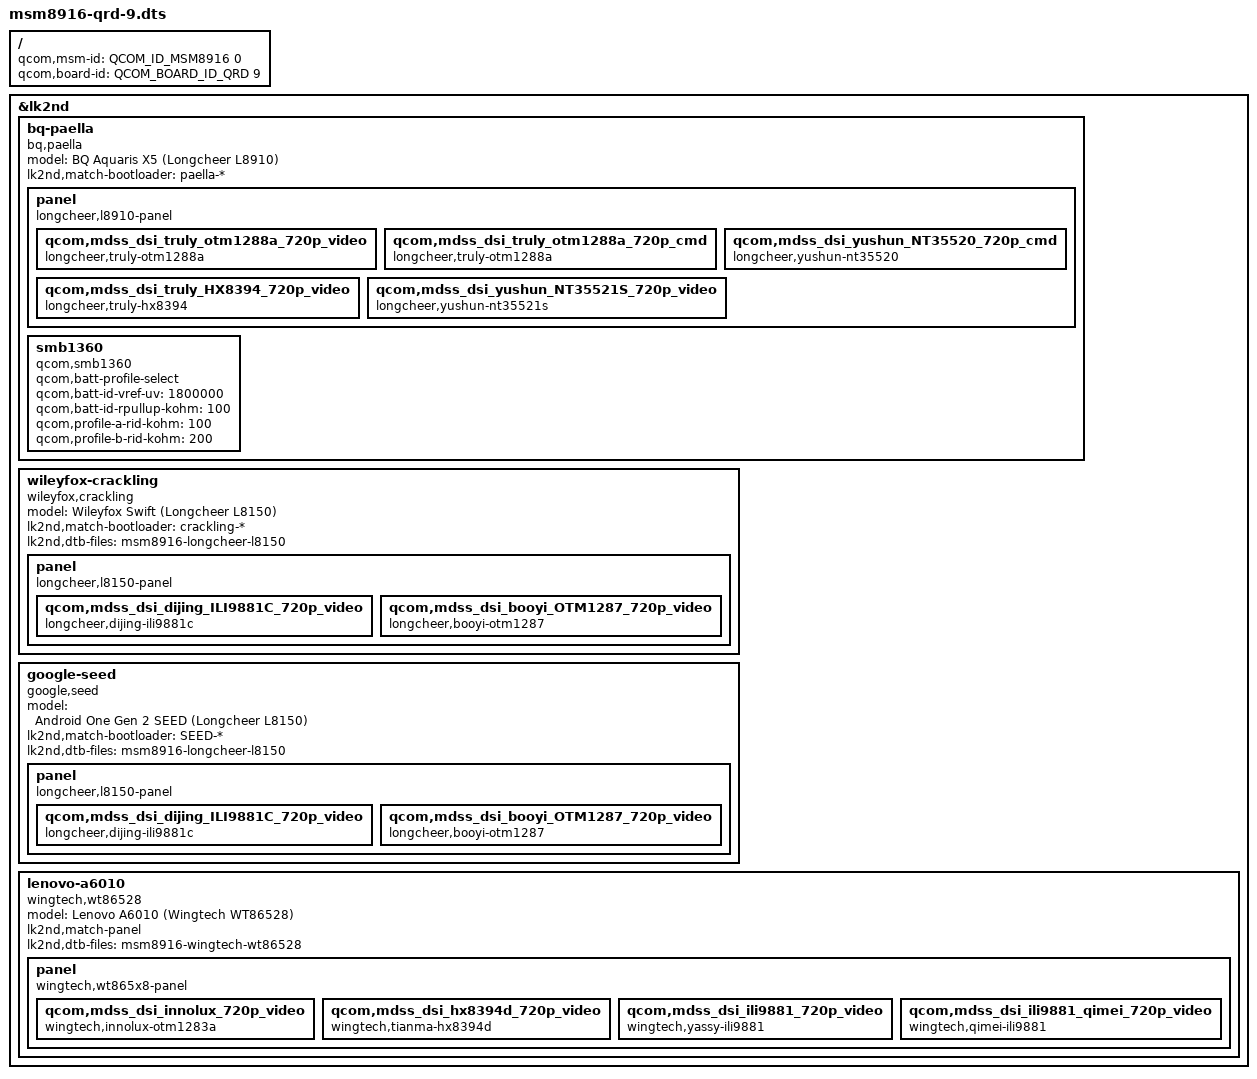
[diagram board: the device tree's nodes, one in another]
// SPDX-License-Identifier: GPL-2.0-only

#include <skeleton64.dtsi>
#include <lk2nd.dtsi>

/ {
	qcom,msm-id = <QCOM_ID_MSM8916 0>;
	qcom,board-id = <QCOM_BOARD_ID_QRD 9>;
};

&lk2nd {
	bq-paella {
		model = "BQ Aquaris X5 (Longcheer L8910)";
		compatible = "bq,paella", "longcheer,l8910";
		lk2nd,match-bootloader = "paella-*";

		panel {
			compatible = "longcheer,l8910-panel", "lk2nd,panel";

			qcom,mdss_dsi_truly_otm1288a_720p_video {
				compatible = "longcheer,truly-otm1288a";
			};
			qcom,mdss_dsi_truly_otm1288a_720p_cmd {
				compatible = "longcheer,truly-otm1288a";
			};
			qcom,mdss_dsi_yushun_NT35520_720p_cmd {
				compatible = "longcheer,yushun-nt35520";
			};
			qcom,mdss_dsi_truly_HX8394_720p_video {
				compatible = "longcheer,truly-hx8394";
			};
			qcom,mdss_dsi_yushun_NT35521S_720p_video {
				compatible = "longcheer,yushun-nt35521s";
			};
		};

		smb1360 {
			compatible = "qcom,smb1360";
			qcom,batt-profile-select;
			qcom,batt-id-vref-uv = <1800000>;
			qcom,batt-id-rpullup-kohm = <100>;
			qcom,profile-a-rid-kohm = <100>;
			qcom,profile-b-rid-kohm = <200>;
		};
	};

	wileyfox-crackling {
		model = "Wileyfox Swift (Longcheer L8150)";
		compatible = "wileyfox,crackling", "longcheer,l8150";
		lk2nd,match-bootloader = "crackling-*";

		lk2nd,dtb-files = "msm8916-longcheer-l8150";

		panel {
			compatible = "longcheer,l8150-panel", "lk2nd,panel";

			/* TODO: qcom,mdss_dsi_truly_otm1288a_720p_video */
			qcom,mdss_dsi_dijing_ILI9881C_720p_video {
				compatible = "longcheer,dijing-ili9881c";
			};
			qcom,mdss_dsi_booyi_OTM1287_720p_video {
				compatible = "longcheer,booyi-otm1287";
			};
		};
	};

	google-seed {
		model = "Android One Gen 2 SEED (Longcheer L8150)";
		compatible = "google,seed", "longcheer,l8150";
		lk2nd,match-bootloader = "SEED-*";

		lk2nd,dtb-files = "msm8916-longcheer-l8150";

		panel {
			compatible = "longcheer,l8150-panel", "lk2nd,panel";

			/* TODO: qcom,mdss_dsi_truly_otm1288a_720p_video */
			qcom,mdss_dsi_dijing_ILI9881C_720p_video {
				compatible = "longcheer,dijing-ili9881c";
			};
			qcom,mdss_dsi_booyi_OTM1287_720p_video {
				compatible = "longcheer,booyi-otm1287";
			};
		};
	};

	lenovo-a6010 {
		model = "Lenovo A6010 (Wingtech WT86528)";
		compatible = "wingtech,wt86528";
		lk2nd,match-panel;

		lk2nd,dtb-files = "msm8916-wingtech-wt86528";

		panel {
			compatible = "wingtech,wt865x8-panel", "lk2nd,panel";

			qcom,mdss_dsi_innolux_720p_video {
				compatible = "wingtech,innolux-otm1283a";
			};
			qcom,mdss_dsi_hx8394d_720p_video {
				compatible = "wingtech,tianma-hx8394d";
			};
			qcom,mdss_dsi_ili9881_720p_video {
				compatible = "wingtech,yassy-ili9881";
			};
			qcom,mdss_dsi_ili9881_qimei_720p_video {
				compatible = "wingtech,qimei-ili9881";
			};
		};
	};
};
